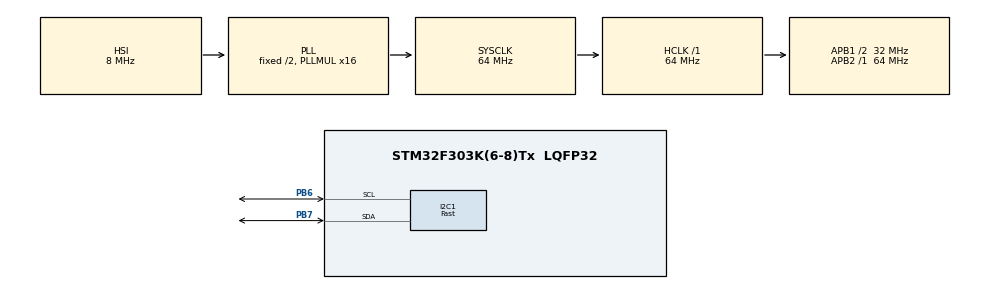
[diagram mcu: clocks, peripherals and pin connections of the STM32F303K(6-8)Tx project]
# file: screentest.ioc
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I2C1.I2C_Speed_Mode=I2C_Fast
I2C1.Timing=0x0000020B
Mcu.Family=STM32F3
Mcu.Name=STM32F303K(6-8)Tx
Mcu.Package=LQFP32
NVIC.PriorityGroup=NVIC_PRIORITYGROUP_4
PB6.Mode=I2C
PB6.Signal=I2C1_SCL
PB7.Mode=I2C
PB7.Signal=I2C1_SDA
ProjectManager.HeapSize=0x200
ProjectManager.StackSize=0x400
ProjectManager.TargetToolchain=STM32CubeIDE
RCC.AHBFreq_Value=64000000
RCC.APB1CLKDivider=RCC_HCLK_DIV2
RCC.APB1Freq_Value=32000000
RCC.APB1TimFreq_Value=64000000
RCC.APB2Freq_Value=64000000
RCC.APB2TimFreq_Value=64000000
RCC.CortexFreq_Value=64000000
RCC.HCLKFreq_Value=64000000
RCC.HSE_VALUE=8000000
RCC.HSI_VALUE=8000000
RCC.PLLMUL=RCC_PLL_MUL16
RCC.SYSCLKFreq_VALUE=64000000
RCC.SYSCLKSourceVirtual=RCC_SYSCLKSOURCE_PLLCLK
board=custom

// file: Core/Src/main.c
/* USER CODE BEGIN Header */
/**
  ******************************************************************************
  * @file           : main.c
  * @brief          : Main program body
  ******************************************************************************
  * @attention
  *
  * Copyright (c) 2023 STMicroelectronics.
  * All rights reserved.
  *
  * This software is licensed under terms that can be found in the LICENSE file
  * in the root directory of this software component.
  * If no LICENSE file comes with this software, it is provided AS-IS.
  *
  ******************************************************************************
  */
/* USER CODE END Header */
#include "main.h"

/* USER CODE BEGIN Includes */

#include "SSD1306.h"
#include "GFX_BW.h"
/* USER CODE END Includes */

/* USER CODE BEGIN PTD */
 typedef struct ball_stuct {
	 float v_x;
	 float v_y;
	 float x;
	 float y;
	 int r;
	 float velocity;
	 int angle;
	 uint8_t index;
 } Ball_structTypeDef;
 Ball_structTypeDef Ball_table[10];
/* USER CODE END PTD */

/* USER CODE BEGIN PM */
 uint16_t y16=315;
 uint16_t xorshift(void)
 {
     y16 ^= y16 << 7;
     y16 ^= y16 >> 9;
     y16 ^= y16 << 8;
     return y16;
 }
/* USER CODE END PM */

I2C_HandleTypeDef hi2c1;

/* USER CODE BEGIN PV */
Ball_structTypeDef Ball1;
Ball_structTypeDef Ball2;

/* USER CODE END PV */

void SystemClock_Config(void);
static void MX_GPIO_Init(void);
static void MX_I2C1_Init(void);

/* USER CODE BEGIN 0 */
void ball_init(Ball_structTypeDef* ball,int r, int x, int y, float v, int angle){
	ball->r=r;
	ball->x=x;
	ball->y=y;
	ball->v_x=1;
	ball->v_y=1;
	ball->velocity=v;
	ball->angle=angle;
	ball->v_x=ball->velocity*sin((ball->angle*M_PI*2)/360);
	ball->v_y=ball->velocity*cos((ball->angle*M_PI*2)/360);
}
void border_check(Ball_structTypeDef* ball){
	if(((ball->y+ball->r)>(SSD1306_LCDHEIGHT-1))||((ball->y-ball->r)<0)){
		ball->v_y=ball->v_y*-1;
	}
	if(((ball->x+ball->r)>(SSD1306_LCDWIDTH-1))||(ball->x-ball->r<0)){
		ball->v_x=ball->v_x*-1;
	}
}

void ball_routine(Ball_structTypeDef* ball){
	ball->x+=ball->v_x;
	ball->y+=ball->v_y;
	border_check(ball);
	GFX_DrawFillCircle((int)ball->x,(int)ball->y,ball->r,WHITE);
}
float distance_p(float x1,float x2,float y1,float y2){
	return(sqrt((x2-x1)*(x2-x1)+(y2-y1)*(y2-y1)));
}
void ball_collision(Ball_structTypeDef* ball1 ,Ball_structTypeDef* ball2 ){
	float distance=distance_p(ball1->x,ball2->x,ball1->y,ball2->y);
	if(distance<=(ball1->r+ball2->r)){
		ball1->v_x=ball1->v_x*-1;
		ball1->v_y=ball1->v_y*-1;
		ball2->v_x=ball2->v_x*-1;
		ball2->v_y=ball2->v_y*-1;
	}
}
/* USER CODE END 0 */

int main(void)
{

  /* MCU Configuration--------------------------------------------------------*/

  /* Reset of all peripherals, Initializes the Flash interface and the Systick. */
  HAL_Init();

  /* Configure the system clock */
  SystemClock_Config();

  /* Initialize all configured peripherals */
  MX_GPIO_Init();
  MX_I2C1_Init();
  /* USER CODE BEGIN 2 */
  __HAL_RCC_I2C1_CLK_ENABLE();
  SSD1306_I2cInit(&hi2c1);
  ball_init(&Ball_table[0],5,32,32,4,50);
  ball_init(&Ball_table[1],5,16,16,6,123);
  /* USER CODE END 2 */

  /* Infinite loop */
  /* USER CODE BEGIN WHILE */
  while (1)
  {
	  SSD1306_Clear(BLACK);
	  ball_routine(&Ball_table[0]);
	  ball_routine(&Ball_table[1]);
	  ball_collision(&Ball_table[0],&Ball_table[1]);
	  SSD1306_Display();

    /* USER CODE END WHILE */

  }
}

void SystemClock_Config(void)
{
  RCC_OscInitTypeDef RCC_OscInitStruct = {0};
  RCC_ClkInitTypeDef RCC_ClkInitStruct = {0};
  RCC_PeriphCLKInitTypeDef PeriphClkInit = {0};

  /** Initializes the RCC Oscillators according to the specified parameters
  * in the RCC_OscInitTypeDef structure.
  */
  RCC_OscInitStruct.OscillatorType = RCC_OSCILLATORTYPE_HSI;
  RCC_OscInitStruct.HSIState = RCC_HSI_ON;
  RCC_OscInitStruct.HSICalibrationValue = RCC_HSICALIBRATION_DEFAULT;
  RCC_OscInitStruct.PLL.PLLState = RCC_PLL_ON;
  RCC_OscInitStruct.PLL.PLLSource = RCC_PLLSOURCE_HSI;
  RCC_OscInitStruct.PLL.PLLMUL = RCC_PLL_MUL16;
  if (HAL_RCC_OscConfig(&RCC_OscInitStruct) != HAL_OK)
  {
    Error_Handler();
  }

  /** Initializes the CPU, AHB and APB buses clocks
  */
  RCC_ClkInitStruct.ClockType = RCC_CLOCKTYPE_HCLK|RCC_CLOCKTYPE_SYSCLK
                              |RCC_CLOCKTYPE_PCLK1|RCC_CLOCKTYPE_PCLK2;
  RCC_ClkInitStruct.SYSCLKSource = RCC_SYSCLKSOURCE_PLLCLK;
  RCC_ClkInitStruct.AHBCLKDivider = RCC_SYSCLK_DIV1;
  RCC_ClkInitStruct.APB1CLKDivider = RCC_HCLK_DIV2;
  RCC_ClkInitStruct.APB2CLKDivider = RCC_HCLK_DIV1;

  if (HAL_RCC_ClockConfig(&RCC_ClkInitStruct, FLASH_LATENCY_2) != HAL_OK)
  {
    Error_Handler();
  }
  PeriphClkInit.PeriphClockSelection = RCC_PERIPHCLK_I2C1;
  PeriphClkInit.I2c1ClockSelection = RCC_I2C1CLKSOURCE_HSI;
  if (HAL_RCCEx_PeriphCLKConfig(&PeriphClkInit) != HAL_OK)
  {
    Error_Handler();
  }
}

static void MX_I2C1_Init(void)
{

  hi2c1.Instance = I2C1;
  hi2c1.Init.Timing = 0x0000020B;
  hi2c1.Init.OwnAddress1 = 0;
  hi2c1.Init.AddressingMode = I2C_ADDRESSINGMODE_7BIT;
  hi2c1.Init.DualAddressMode = I2C_DUALADDRESS_DISABLE;
  hi2c1.Init.OwnAddress2 = 0;
  hi2c1.Init.OwnAddress2Masks = I2C_OA2_NOMASK;
  hi2c1.Init.GeneralCallMode = I2C_GENERALCALL_DISABLE;
  hi2c1.Init.NoStretchMode = I2C_NOSTRETCH_DISABLE;
  if (HAL_I2C_Init(&hi2c1) != HAL_OK)
  {
    Error_Handler();
  }

  /** Configure Analogue filter
  */
  if (HAL_I2CEx_ConfigAnalogFilter(&hi2c1, I2C_ANALOGFILTER_ENABLE) != HAL_OK)
  {
    Error_Handler();
  }

  /** Configure Digital filter
  */
  if (HAL_I2CEx_ConfigDigitalFilter(&hi2c1, 0) != HAL_OK)
  {
    Error_Handler();
  }

}

static void MX_GPIO_Init(void)
{

  /* GPIO Ports Clock Enable */
  __HAL_RCC_GPIOB_CLK_ENABLE();

}

void Error_Handler(void)
{
  __disable_irq();
  while (1)
  {
  }
}
